# STM32U3C5xx register map
File version: 1.0
Registers are 32-bit, read-write, reset 0x0 unless marked. A register's access mark holds for its fields unless they carry their own. Offsets are from the block's base; [hi:lo] are bit positions; {n}, {i} and the like mark numbered series.

## GTZC_TZSC1 — Global TrustZone Controller
Base 0x40032400
0x00 CR — TZSC control register
  [0] LCK
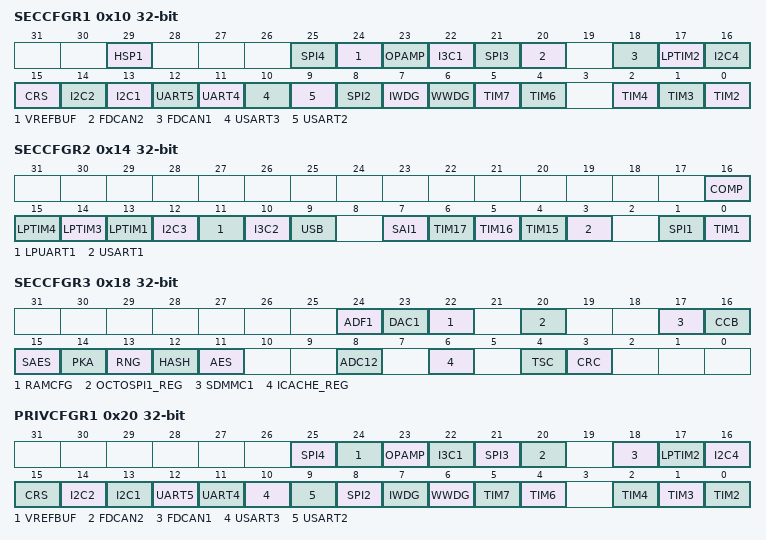
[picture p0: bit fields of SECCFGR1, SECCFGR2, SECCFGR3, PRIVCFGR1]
0x10 SECCFGR1 — TZSC secure configuration register 1
  [29] HSP1, [25] SPI4, [24] VREFBUF, [23] OPAMP, [22] I3C1, [21] SPI3, [20] FDCAN2, [18] FDCAN1, [17] LPTIM2, [16] I2C4, [15] CRS, [14] I2C2, [13] I2C1, [12] UART5, [11] UART4, [10] USART3, [9] USART2, [8] SPI2, [7] IWDG, [6] WWDG, [5] TIM7, [4] TIM6, [2] TIM4, [1] TIM3, [0] TIM2
0x14 SECCFGR2 — TZSC secure configuration register 2
  [16] COMP, [15] LPTIM4, [14] LPTIM3, [13] LPTIM1, [12] I2C3, [11] LPUART1, [10] I3C2, [9] USB, [7] SAI1, [6] TIM17, [5] TIM16, [4] TIM15, [3] USART1, [1] SPI1, [0] TIM1
0x18 SECCFGR3 — TZSC secure configuration register 3
  [24] ADF1, [23] DAC1, [22] RAMCFG, [20] OCTOSPI1_REG, [17] SDMMC1, [16] CCB, [15] SAES, [14] PKA, [13] RNG, [12] HASH, [11] AES, [8] ADC12, [6] ICACHE_REG, [4] TSC, [3] CRC
0x20 PRIVCFGR1 — TZSC privilege configuration register 1
  [25] SPI4, [24] VREFBUF, [23] OPAMP, [22] I3C1, [21] SPI3, [20] FDCAN2, [18] FDCAN1, [17] LPTIM2, [16] I2C4, [15] CRS, [14] I2C2, [13] I2C1, [12] UART5, [11] UART4, [10] USART3, [9] USART2, [8] SPI2, [7] IWDG, [6] WWDG, [5] TIM7, [4] TIM6, [2] TIM4, [1] TIM3, [0] TIM2
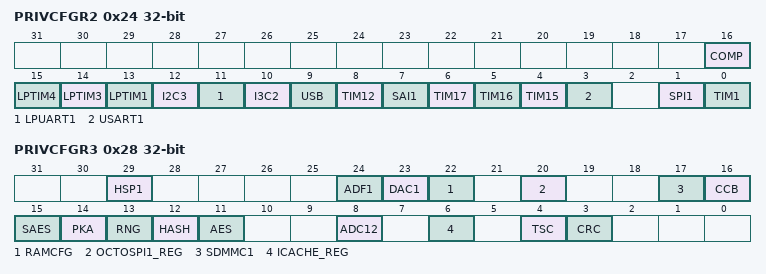
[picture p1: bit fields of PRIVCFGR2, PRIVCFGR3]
0x24 PRIVCFGR2 — TZSC privilege configuration register 2
  [16] COMP, [15] LPTIM4, [14] LPTIM3, [13] LPTIM1, [12] I2C3, [11] LPUART1, [10] I3C2, [9] USB, [8] TIM12, [7] SAI1, [6] TIM17, [5] TIM16, [4] TIM15, [3] USART1, [1] SPI1, [0] TIM1
0x28 PRIVCFGR3 — TZSC privilege configuration register 3
  [29] HSP1, [24] ADF1, [23] DAC1, [22] RAMCFG, [20] OCTOSPI1_REG, [17] SDMMC1, [16] CCB, [15] SAES, [14] PKA, [13] RNG, [12] HASH, [11] AES, [8] ADC12, [6] ICACHE_REG, [4] TSC, [3] CRC

## GTZC_MPCBB1
Base 0x40032C00
Same registers: GTZC_MPCBB2 0x40033000, GTZC_MPCBB3 0x40033400, GTZC_MPCBB4 0x40033800
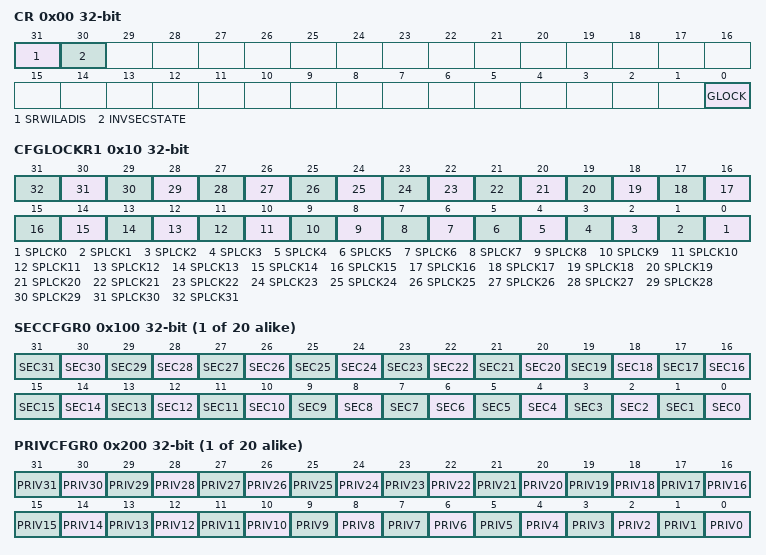
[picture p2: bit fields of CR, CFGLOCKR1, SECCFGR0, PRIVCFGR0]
0x00 CR — MPCBBx control register
  [31] SRWILADIS, [30] INVSECSTATE, [0] GLOCK
0x10 CFGLOCKR1 — MPCBBx Configuration lock register
  [n] SPLCK{n} (n=0..31)
{0x100+4i} SECCFGR{i} (i=0..19) — MPCBBx security configuration registers
  [n] SEC{n} (n=0..31)
{0x200+4i} PRIVCFGR{i} (i=0..19) — MPCBBx privilege configuration registers
  [n] PRIV{n} (n=0..31)

## SYSCFG — System configuration controller
Base 0x40040400
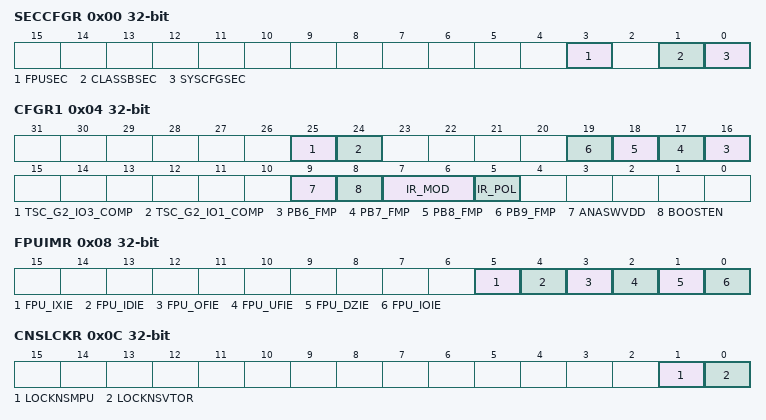
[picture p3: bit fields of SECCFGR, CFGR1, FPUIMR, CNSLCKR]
0x00 SECCFGR — SYSCFG secure configuration register
  [3] FPUSEC — FPU SYSCFG security enable
  [1] CLASSBSEC — ClassB SYSCFG security enable
  [0] SYSCFGSEC — SYSCFG clock control security enable
0x04 CFGR1 — SYSCFG configuration register 1
  [25] TSC_G2_IO3_COMP — Comparator mode for G2_IO3 on PB6
  [24] TSC_G2_IO1_COMP — Comparator mode for G2_IO1 on PB4
  [n+10] PB{n}_FMP (n=6..9) — PB{n} Fast mode plus
  [9] ANASWVDD — GPIO analog switch control voltage selection
  [8] BOOSTEN — I/O analog switch voltage booster enable
  [7:6] IR_MOD — IR Modulation Envelope signal selection
  [5] IR_POL — IR output polarity selection
0x08 FPUIMR — SYSCFG FPU interrupt mask register
  [5] FPU_IXIE — Floating point unit interrupt enable bit - inexact
  [4] FPU_IDIE — Floating point unit interrupt enable bit - input denormal
  [3] FPU_OFIE — Floating point unit interrupt enable bit - overflow
  [2] FPU_UFIE — Floating point unit interrupt enable bit - underflow
  [1] FPU_DZIE — Floating point unit interrupt enable bit - divide-by-zero
  [0] FPU_IOIE — Floating point unit interrupt enable bit - invalid operation
0x0C CNSLCKR — SYSCFG CPU non-secure lock register
  [1] LOCKNSMPU — Disable Non-Secure MPU registers writes by SW or debug agent
  [0] LOCKNSVTOR — Disable VTOR_NS register writes by SW or debug agent
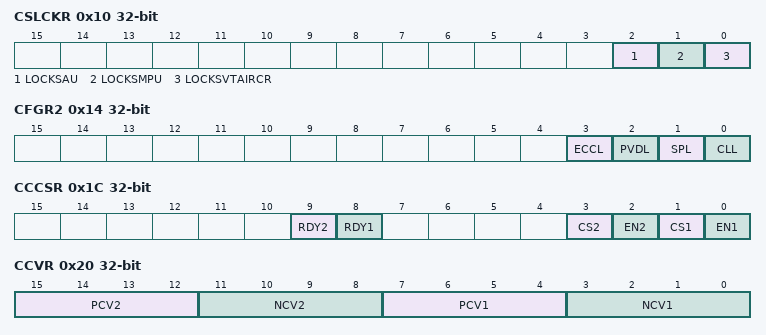
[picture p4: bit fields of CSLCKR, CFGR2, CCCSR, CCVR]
0x10 CSLCKR — SYSCFG CPU secure lock register
  [2] LOCKSAU — Disable changes to SAU registers
  [1] LOCKSMPU — Disable changes to the secure MPU registers writes by SW or debug agent
  [0] LOCKSVTAIRCR — Disable changes to the secure vector table address, handling of system faults
0x14 CFGR2 — SYSCFG configuration register 2
  [3] ECCL — ECC Lock
  [2] PVDL — PVD Lock
  [1] SPL — SRAM parity Lock
  [0] CLL — Core Lockup Lock
0x1C CCCSR — SYSCFG Conpensaion Cell Control&Status register
  [9] RDY2 — VDDIO compensation cell ready flag
  [8] RDY1 — VDD compensation cell ready flag
  [3] CS2 — Code selection for VDDIO power rail
  [2] EN2 — Enable compensation cell for VDDIO power rail
  [1] CS1 — Code selection for VDD power rail
  [0] EN1 — Enable compensation cell for VDD power rail
0x20 CCVR — SYSCFG Conpensaion Cell value register
  [15:12] PCV2 — PMOS compensation value for VDDIO Power Rail
  [11:8] NCV2 — NMOS compensation value for VDDIO Power Rail
  [7:4] PCV1 — PMOS compensation value for VDD Power Rail
  [3:0] NCV1 — NMOS compensation value for VDD Power Rail
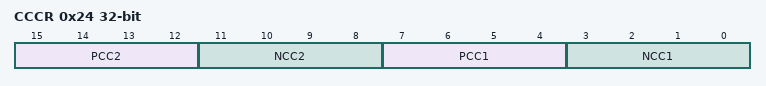
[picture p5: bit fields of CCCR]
0x24 CCCR — SYSCFG Conpensaion Cell Code register
  [15:12] PCC2 — PMOS compensation code for VDDIO Power Rail
  [11:8] NCC2 — NMOS compensation code for VDDIO Power Rail
  [7:4] PCC1 — PMOS compensation code for VDD Power Rail
  [3:0] NCC1 — NMOS compensation code for VDD Power Rail
0x2C RSSCMDR — SYSCFG RSS command mode register
  [15:0] RSSCMD — RSS commands
